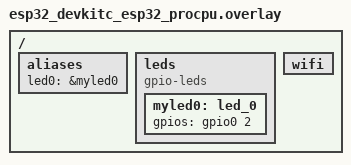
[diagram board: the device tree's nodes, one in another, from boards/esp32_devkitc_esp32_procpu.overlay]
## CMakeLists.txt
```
cmake_minimum_required(VERSION 3.20.0)

find_package(Zephyr REQUIRED HINTS $ENV{ZEPHYR_BASE})
project(app1)

target_sources(app PRIVATE src/main.c)
```

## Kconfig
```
menu "Example App Config"

module = EXAMPLE_APP
module-str = EXAMPLE_APP
source "subsys/logging/Kconfig.template.log_config"

config EXAMPLE_APP_SLEEP
    int "seconds to sleep between LED ON-OFF"
    default 2
    help
        Seconds to sleep between LED ON-OFF

endmenu

source "Kconfig.zephyr"
```

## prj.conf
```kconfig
CONFIG_GPIO=y

CONFIG_LOG=y
CONFIG_LOG_MODE_DEFERRED=n
CONFIG_LOG_MODE_IMMEDIATE=y
CONFIG_LOG_DEFAULT_LEVEL=3
```

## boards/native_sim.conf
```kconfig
# Enable GPIO emulator
CONFIG_GPIO=y
CONFIG_GPIO_EMUL=y

# Optional: Enable more verbose logging to see LED state changes
# CONFIG_LOG_MODE_IMMEDIATE=y
```

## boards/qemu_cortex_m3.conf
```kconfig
# Enable GPIO emulator
CONFIG_GPIO=y
CONFIG_GPIO_EMUL=y

# Optional: Enable console output
CONFIG_PRINTK=y
CONFIG_CONSOLE=y

# Disable kernel debug logs to reduce noise
CONFIG_KERNEL_LOG_LEVEL_OFF=y
CONFIG_QEMU_ICOUNT_SLEEP=y
```

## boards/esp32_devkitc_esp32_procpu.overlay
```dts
/ {

     aliases {
             led0 = &myled0;
     };

     leds {
             compatible = "gpio-leds";
             myled0: led_0 {
                     gpios = <&gpio0 2 GPIO_ACTIVE_HIGH>;
             };
     };

     wifi {
         status = "okay";
     };

};
```

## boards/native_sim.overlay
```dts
/ {
     aliases {
             led0 = &led0;
     };

     leds {
             compatible = "gpio-leds";
             led0: led_0 {
                     gpios = <&gpio0 0 GPIO_ACTIVE_HIGH>;
                     label = "Simulated LED 0";
             };
     };
};

&gpio0 {
     status = "okay";
     ngpios = <32>;
};
```

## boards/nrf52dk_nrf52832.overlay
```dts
/ {
     aliases {
             led0 = &led0;
     };
};

&led0 {
     status = "okay";
};
```

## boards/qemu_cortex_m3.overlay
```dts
/ {
	aliases {
		led0 = &led0;
	};

	leds {
		compatible = "gpio-leds";
		led0: led_0 {
			gpios = <&gpio0 0 0>;
			label = "QEMU LED 0";
		};
	};
};
```

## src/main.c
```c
#include <stdio.h>
#include <zephyr/drivers/gpio.h>
#include <zephyr/kernel.h>
#include <zephyr/logging/log.h>

LOG_MODULE_REGISTER(main, CONFIG_EXAMPLE_APP_LOG_LEVEL);

#define LED0_NODE DT_ALIAS(led0)

static const struct gpio_dt_spec led = GPIO_DT_SPEC_GET(LED0_NODE, gpios);

int main(void)
{
	int ret;
	bool led_state = true;

	if (!gpio_is_ready_dt(&led)) {
		LOG_ERR("Error, gpio is not ready\n");
		return 0;
	}

	ret = gpio_pin_configure_dt(&led, GPIO_OUTPUT_ACTIVE);
	if (ret < 0) {
		LOG_ERR("Error configuring gpio: %d\n", ret);
		return 0;
	}

	LOG_DBG("LED configured and ready to blink\n");
	while (1) {
		ret = gpio_pin_toggle_dt(&led);
		if (ret < 0) {
			LOG_ERR("Error toggling led\n");
			return 0;
		}

		led_state = !led_state;
		printf("LED is now: %s\n", led_state ? "ON" : "OFF");

		k_sleep(K_SECONDS(CONFIG_EXAMPLE_APP_SLEEP));
	}
	return 0;
}
```
